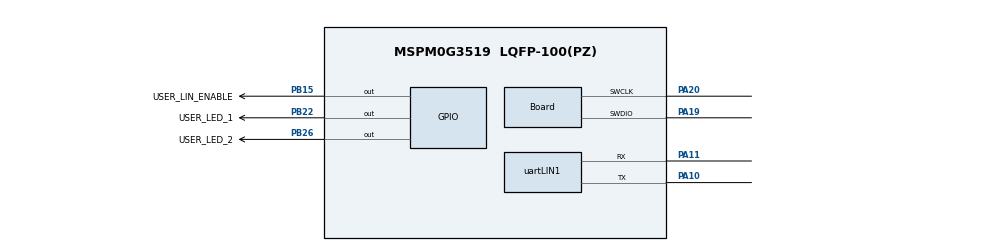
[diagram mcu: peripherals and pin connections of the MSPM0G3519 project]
//@cliArgs --device "MSPM0G351X" --package "LQFP-100(PZ)" --part "Default"
//@v2CliArgs --device "MSPM0G3519" --package "LQFP-100(PZ)"
// @cliArgs --board /ti/boards/LP_MSPM0G3519 --rtos nortos

/**
 * Import the modules used in this configuration.
 */
const Board    = scripting.addModule("/ti/driverlib/Board");
const GPIO     = scripting.addModule("/ti/driverlib/GPIO", {}, false);
const GPIO1    = GPIO.addInstance();
const GPIO2    = GPIO.addInstance();
const SYSCTL   = scripting.addModule("/ti/driverlib/SYSCTL");
const TIMER    = scripting.addModule("/ti/driverlib/TIMER", {}, false);
const TIMER1   = TIMER.addInstance();
const uartLIN  = scripting.addModule("/ti/driverlib/uartLIN", {}, false);
const uartLIN1 = uartLIN.addInstance();

/**
 * Write custom configuration values to the imported modules.
 */
Board.peripheral.$assign          = "DEBUGSS";
Board.peripheral.swclkPin.$assign = "PA20";
Board.peripheral.swdioPin.$assign = "PA19";

GPIO1.$name                         = "GPIO_LEDS";
GPIO1.port                          = "PORTB";
GPIO1.portSegment                   = "Upper";
GPIO1.associatedPins.create(2);
GPIO1.associatedPins[0].$name       = "USER_LED_1";
GPIO1.associatedPins[0].assignedPin = "22";
GPIO1.associatedPins[0].pin.$assign = "PB22";
GPIO1.associatedPins[1].$name       = "USER_LED_2";
GPIO1.associatedPins[1].assignedPin = "26";
GPIO1.associatedPins[1].pin.$assign = "PB26";

GPIO2.$name                         = "GPIO_LIN_ENABLE";
GPIO2.port                          = "PORTB";
GPIO2.portSegment                   = "Lower";
GPIO2.associatedPins[0].$name       = "USER_LIN_ENABLE";
GPIO2.associatedPins[0].assignedPin = "15";
GPIO2.associatedPins[0].pin.$assign = "PB15";

SYSCTL.clockTreeEn           = true;
SYSCTL.forceDefaultClkConfig = true;

TIMER1.$name              = "TIMER_0";
TIMER1.timerClkSrc        = "LFCLK";
TIMER1.interrupts         = ["ZERO"];
TIMER1.peripheral.$assign = "TIMG0";

uartLIN1.$name                    = "LIN_0";
uartLIN1.profile                  = "CONFIG_PROFILE_1";
uartLIN1.peripheral.$assign       = "UART0";
uartLIN1.peripheral.rxPin.$assign = "PA11";
uartLIN1.peripheral.txPin.$assign = "PA10";

const ProjectConfig              = scripting.addModule("/ti/project_config/ProjectConfig", {}, false);
ProjectConfig.migrationCondition = true;
